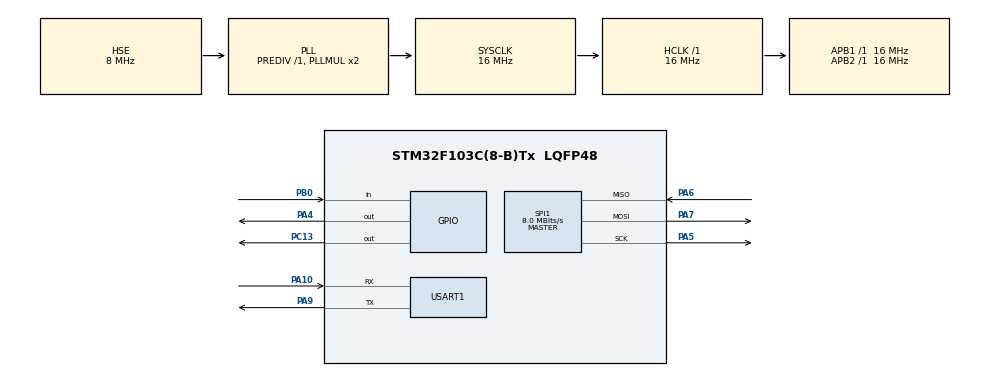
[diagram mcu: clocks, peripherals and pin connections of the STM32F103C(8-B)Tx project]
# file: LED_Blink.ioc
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FREERTOS.Tasks01=defaultTask,24,128,StartDefaultTask,Default,NULL,Dynamic,NULL,NULL;CANTxTask,24,256,StartCANTxTask,Default,NULL,Dynamic,NULL,NULL;UARTLogTask,8,256,StartUARTLogTask,Default,NULL,Dynamic,NULL,NULL
Mcu.Family=STM32F1
Mcu.Name=STM32F103C(8-B)Tx
Mcu.Package=LQFP48
NVIC.PriorityGroup=NVIC_PRIORITYGROUP_4
NVIC.USART1_IRQn=true\:5\:0\:false\:false\:true\:true\:true\:true\:true
PA10.Mode=Asynchronous
PA10.Signal=USART1_RX
PA13.Mode=Serial_Wire
PA13.Signal=SYS_JTMS-SWDIO
PA14.Mode=Serial_Wire
PA14.Signal=SYS_JTCK-SWCLK
PA4.Signal=GPIO_Output
PA5.Mode=Full_Duplex_Master
PA5.Signal=SPI1_SCK
PA6.Mode=Full_Duplex_Master
PA6.Signal=SPI1_MISO
PA7.Mode=Full_Duplex_Master
PA7.Signal=SPI1_MOSI
PA9.Mode=Asynchronous
PA9.Signal=USART1_TX
PB0.Signal=GPIO_Input
PC13-TAMPER-RTC.Signal=GPIO_Output
PD0-OSC_IN.Mode=HSE-External-Oscillator
PD0-OSC_IN.Signal=RCC_OSC_IN
PD1-OSC_OUT.Mode=HSE-External-Oscillator
PD1-OSC_OUT.Signal=RCC_OSC_OUT
ProjectManager.HeapSize=0x200
ProjectManager.StackSize=0x400
ProjectManager.TargetToolchain=STM32CubeIDE
RCC.AHBFreq_Value=16000000
RCC.APB1Freq_Value=16000000
RCC.APB1TimFreq_Value=16000000
RCC.APB2Freq_Value=16000000
RCC.APB2TimFreq_Value=16000000
RCC.HCLKFreq_Value=16000000
RCC.PLLSourceVirtual=RCC_PLLSOURCE_HSE
RCC.SYSCLKFreq_VALUE=16000000
RCC.SYSCLKSource=RCC_SYSCLKSOURCE_PLLCLK
RCC.USBFreq_Value=16000000
SPI1.CalculateBaudRate=8.0 MBits/s
SPI1.Direction=SPI_DIRECTION_2LINES
SPI1.Mode=SPI_MODE_MASTER
SPI1.VirtualType=VM_MASTER
USART1.VirtualMode=VM_ASYNC
VP_FREERTOS_VS_CMSIS_V2.Mode=CMSIS_V2
board=custom

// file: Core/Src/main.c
/* USER CODE BEGIN Header */
/**
  ******************************************************************************
  * @file           : main.c
  * @brief          : CAN Node1 - Sender with FreeRTOS
  ******************************************************************************
  */
/* USER CODE END Header */
#include "main.h"
#include "cmsis_os.h"

/* USER CODE BEGIN Includes */
#include "mcp2515.h"
#include <stdio.h>
#include <string.h>
/* USER CODE END Includes */

SPI_HandleTypeDef hspi1;

UART_HandleTypeDef huart1;

/* Definitions for defaultTask */
osThreadId_t defaultTaskHandle;
const osThreadAttr_t defaultTask_attributes = {
  .name = "defaultTask",
  .stack_size = 128 * 4,
  .priority = (osPriority_t) osPriorityNormal,
};
/* Definitions for CANTxTask */
osThreadId_t CANTxTaskHandle;
const osThreadAttr_t CANTxTask_attributes = {
  .name = "CANTxTask",
  .stack_size = 256 * 4,
  .priority = (osPriority_t) osPriorityNormal,
};
/* Definitions for UARTLogTask */
osThreadId_t UARTLogTaskHandle;
const osThreadAttr_t UARTLogTask_attributes = {
  .name = "UARTLogTask",
  .stack_size = 256 * 4,
  .priority = (osPriority_t) osPriorityLow,
};

void SystemClock_Config(void);
static void MX_GPIO_Init(void);
static void MX_USART1_UART_Init(void);
static void MX_SPI1_Init(void);
void StartDefaultTask(void *argument);
void StartCANTxTask(void *argument);
void StartUARTLogTask(void *argument);

int main(void)
{

  /* MCU Configuration--------------------------------------------------------*/

  /* Reset of all peripherals, Initializes the Flash interface and the Systick. */
  HAL_Init();

  /* Configure the system clock */
  SystemClock_Config();

  /* Initialize all configured peripherals */
  MX_GPIO_Init();
  MX_USART1_UART_Init();
  MX_SPI1_Init();
  /* USER CODE BEGIN 2 */
  MCP2515_Deselect();
  HAL_Delay(100);
  char msg[80];
  sprintf(msg, "Node1 FreeRTOS Booting...\r\n");
  HAL_UART_Transmit(&huart1, (uint8_t*)msg, strlen(msg), 100);
  /* USER CODE END 2 */

  /* Init scheduler */
  osKernelInitialize();

  /* USER CODE BEGIN RTOS_MUTEX */
  extern void MX_FREERTOS_Init(void);
  MX_FREERTOS_Init();
  /* USER CODE END RTOS_MUTEX */

  /* Create the thread(s) */
  /* creation of defaultTask */
  defaultTaskHandle = osThreadNew(StartDefaultTask, NULL, &defaultTask_attributes);

  /* creation of CANTxTask */
  CANTxTaskHandle = osThreadNew(StartCANTxTask, NULL, &CANTxTask_attributes);

  /* creation of UARTLogTask */
  UARTLogTaskHandle = osThreadNew(StartUARTLogTask, NULL, &UARTLogTask_attributes);

  /* Start scheduler */
  osKernelStart();

  /* We should never get here as control is now taken by the scheduler */

  /* Infinite loop */
  while (1)
  {

  }
}

void SystemClock_Config(void)
{
  RCC_OscInitTypeDef RCC_OscInitStruct = {0};
  RCC_ClkInitTypeDef RCC_ClkInitStruct = {0};

  /** Initializes the RCC Oscillators according to the specified parameters
  * in the RCC_OscInitTypeDef structure.
  */
  RCC_OscInitStruct.OscillatorType = RCC_OSCILLATORTYPE_HSE;
  RCC_OscInitStruct.HSEState = RCC_HSE_ON;
  RCC_OscInitStruct.HSEPredivValue = RCC_HSE_PREDIV_DIV1;
  RCC_OscInitStruct.HSIState = RCC_HSI_ON;
  RCC_OscInitStruct.PLL.PLLState = RCC_PLL_ON;
  RCC_OscInitStruct.PLL.PLLSource = RCC_PLLSOURCE_HSE;
  RCC_OscInitStruct.PLL.PLLMUL = RCC_PLL_MUL2;
  if (HAL_RCC_OscConfig(&RCC_OscInitStruct) != HAL_OK)
  {
    Error_Handler();
  }

  /** Initializes the CPU, AHB and APB buses clocks
  */
  RCC_ClkInitStruct.ClockType = RCC_CLOCKTYPE_HCLK|RCC_CLOCKTYPE_SYSCLK
                              |RCC_CLOCKTYPE_PCLK1|RCC_CLOCKTYPE_PCLK2;
  RCC_ClkInitStruct.SYSCLKSource = RCC_SYSCLKSOURCE_PLLCLK;
  RCC_ClkInitStruct.AHBCLKDivider = RCC_SYSCLK_DIV1;
  RCC_ClkInitStruct.APB1CLKDivider = RCC_HCLK_DIV1;
  RCC_ClkInitStruct.APB2CLKDivider = RCC_HCLK_DIV1;

  if (HAL_RCC_ClockConfig(&RCC_ClkInitStruct, FLASH_LATENCY_0) != HAL_OK)
  {
    Error_Handler();
  }
}

static void MX_SPI1_Init(void)
{

  /* SPI1 parameter configuration*/
  hspi1.Instance = SPI1;
  hspi1.Init.Mode = SPI_MODE_MASTER;
  hspi1.Init.Direction = SPI_DIRECTION_2LINES;
  hspi1.Init.DataSize = SPI_DATASIZE_8BIT;
  hspi1.Init.CLKPolarity = SPI_POLARITY_LOW;
  hspi1.Init.CLKPhase = SPI_PHASE_1EDGE;
  hspi1.Init.NSS = SPI_NSS_SOFT;
  hspi1.Init.BaudRatePrescaler = SPI_BAUDRATEPRESCALER_2;
  hspi1.Init.FirstBit = SPI_FIRSTBIT_MSB;
  hspi1.Init.TIMode = SPI_TIMODE_DISABLE;
  hspi1.Init.CRCCalculation = SPI_CRCCALCULATION_DISABLE;
  hspi1.Init.CRCPolynomial = 10;
  if (HAL_SPI_Init(&hspi1) != HAL_OK)
  {
    Error_Handler();
  }

}

static void MX_USART1_UART_Init(void)
{

  huart1.Instance = USART1;
  huart1.Init.BaudRate = 115200;
  huart1.Init.WordLength = UART_WORDLENGTH_8B;
  huart1.Init.StopBits = UART_STOPBITS_1;
  huart1.Init.Parity = UART_PARITY_NONE;
  huart1.Init.Mode = UART_MODE_TX_RX;
  huart1.Init.HwFlowCtl = UART_HWCONTROL_NONE;
  huart1.Init.OverSampling = UART_OVERSAMPLING_16;
  if (HAL_UART_Init(&huart1) != HAL_OK)
  {
    Error_Handler();
  }

}

static void MX_GPIO_Init(void)
{
  GPIO_InitTypeDef GPIO_InitStruct = {0};

  /* GPIO Ports Clock Enable */
  __HAL_RCC_GPIOC_CLK_ENABLE();
  __HAL_RCC_GPIOD_CLK_ENABLE();
  __HAL_RCC_GPIOA_CLK_ENABLE();
  __HAL_RCC_GPIOB_CLK_ENABLE();

  /*Configure GPIO pin Output Level */
  HAL_GPIO_WritePin(GPIOC, GPIO_PIN_13, GPIO_PIN_RESET);

  /*Configure GPIO pin Output Level */
  HAL_GPIO_WritePin(GPIOA, GPIO_PIN_4, GPIO_PIN_RESET);

  /*Configure GPIO pin : PC13 */
  GPIO_InitStruct.Pin = GPIO_PIN_13;
  GPIO_InitStruct.Mode = GPIO_MODE_OUTPUT_PP;
  GPIO_InitStruct.Pull = GPIO_NOPULL;
  GPIO_InitStruct.Speed = GPIO_SPEED_FREQ_LOW;
  HAL_GPIO_Init(GPIOC, &GPIO_InitStruct);

  /*Configure GPIO pin : PA4 */
  GPIO_InitStruct.Pin = GPIO_PIN_4;
  GPIO_InitStruct.Mode = GPIO_MODE_OUTPUT_PP;
  GPIO_InitStruct.Pull = GPIO_NOPULL;
  GPIO_InitStruct.Speed = GPIO_SPEED_FREQ_LOW;
  HAL_GPIO_Init(GPIOA, &GPIO_InitStruct);

  /*Configure GPIO pin : PB0 */
  GPIO_InitStruct.Pin = GPIO_PIN_0;
  GPIO_InitStruct.Mode = GPIO_MODE_INPUT;
  GPIO_InitStruct.Pull = GPIO_NOPULL;
  HAL_GPIO_Init(GPIOB, &GPIO_InitStruct);

}

/* USER CODE BEGIN Header_StartDefaultTask */

void Error_Handler(void)
{
  __disable_irq();
  while (1)
  {
  }
}

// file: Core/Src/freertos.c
#include "FreeRTOS.h"
#include "task.h"
#include "main.h"
#include "cmsis_os.h"
#include "mcp2515.h"
#include <stdio.h>
#include <string.h>
#include <stdlib.h>

extern UART_HandleTypeDef huart1;

osMutexId_t spiMutexHandle;
osMessageQueueId_t uartQueueHandle;

static uint8_t can_open = 0;
static uint8_t uart_rx_byte;
static char cmd_buf[32];
static int cmd_pos = 0;
static uint8_t cmd_ready = 0;
static char pending_cmd[32];

void StartDefaultTask(void *argument);
void StartCANTxTask(void *argument);
void StartUARTLogTask(void *argument);
void StartMonitorTask(void *argument);

void MX_FREERTOS_Init(void) {
    spiMutexHandle = osMutexNew(NULL);
}

void vApplicationStackOverflowHook(TaskHandle_t xTask, char *pcTaskName)
{
    HAL_UART_Transmit(&huart1, (uint8_t*)"STACK OVERFLOW: ", 16, 100);
    HAL_UART_Transmit(&huart1, (uint8_t*)pcTaskName, strlen(pcTaskName), 100);
    HAL_UART_Transmit(&huart1, (uint8_t*)"\r\n", 2, 100);
    while(1) {}
}

void HAL_UART_RxCpltCallback(UART_HandleTypeDef *huart)
{
    if (huart->Instance == USART1) {
        uint8_t byte = uart_rx_byte;
        if (byte == '\r' || byte == '\n') {
            if (cmd_pos > 0) {
                cmd_buf[cmd_pos] = 0;
                memcpy(pending_cmd, cmd_buf, cmd_pos + 1);
                cmd_ready = 1;
                cmd_pos = 0;
                memset(cmd_buf, 0, sizeof(cmd_buf));
            }
        } else if (cmd_pos < 31) {
            cmd_buf[cmd_pos++] = byte;
        }

        HAL_UART_Receive_IT(&huart1, &uart_rx_byte, 1);
    }
}

void slcan_parse(char *cmd)
{
    char debug[40];
    sprintf(debug, "CMD:[%s]\r\n", cmd);
    HAL_UART_Transmit(&huart1, (uint8_t*)debug, strlen(debug), 100);

    uint8_t response = '\r';

    if (cmd[0] == 'S') {
        HAL_UART_Transmit(&huart1, &response, 1, 100);
    }
    else if (cmd[0] == 'O') {
        can_open = 1;
        HAL_UART_Transmit(&huart1, &response, 1, 100);
    }
    else if (cmd[0] == 'C') {
        can_open = 0;
        HAL_UART_Transmit(&huart1, &response, 1, 100);
    }
    else if (cmd[0] == 't' && can_open) {
        uint16_t id = 0;
        uint8_t dlc = 0;
        uint8_t data[8] = {0};

        char id_str[4] = {cmd[1], cmd[2], cmd[3], 0};
        id = (uint16_t)strtol(id_str, NULL, 16);

        dlc = cmd[4] - '0';
        if (dlc > 8) dlc = 8;

        for (int i = 0; i < dlc; i++) {
            char byte_str[3] = {cmd[5 + i*2], cmd[6 + i*2], 0};
            data[i] = (uint8_t)strtol(byte_str, NULL, 16);
        }

        char tx_debug[40];
        sprintf(tx_debug, "TX ID=0x%03X DLC=%d\r\n", id, dlc);
        HAL_UART_Transmit(&huart1, (uint8_t*)tx_debug, strlen(tx_debug), 100);

        osMutexAcquire(spiMutexHandle, osWaitForever);
        MCP2515_SendFrame(id, data, dlc);
        osMutexRelease(spiMutexHandle);

        HAL_UART_Transmit(&huart1, &response, 1, 100);
    }
    else if (cmd[0] == 'F') {
        osMutexAcquire(spiMutexHandle, osWaitForever);
        uint8_t eflg = MCP2515_ReadRegister(0x2D);
        osMutexRelease(spiMutexHandle);
        char resp[8];
        sprintf(resp, "F%02X\r", eflg);
        HAL_UART_Transmit(&huart1, (uint8_t*)resp, strlen(resp), 100);
    }
    else if (cmd[0] == 'V') {
        HAL_UART_Transmit(&huart1, (uint8_t*)"V0101\r", 6, 100);
    }
    else {
        uint8_t err = 0x07;
        HAL_UART_Transmit(&huart1, &err, 1, 100);
    }
}

void slcan_receive(void)
{
    uint8_t canintf = MCP2515_ReadRegister(0x2C);
    if (!(canintf & 0x03)) return;

    uint8_t cmd = (canintf & 0x01) ? 0x90 : 0x94;
    uint8_t buf[13] = {0};
    MCP2515_Select();
    HAL_SPI_Transmit(&hspi1, &cmd, 1, 100);
    HAL_SPI_Receive(&hspi1, buf, 13, 100);
    MCP2515_Deselect();

    uint16_t id = ((uint16_t)buf[0] << 3) | (buf[1] >> 5);
    uint8_t dlc = buf[4] & 0x0F;

    char slcan_msg[32];
    int pos = 0;
    pos += sprintf(slcan_msg + pos, "t%03X%d", id, dlc);
    for (int i = 0; i < dlc; i++) {
        pos += sprintf(slcan_msg + pos, "%02X", buf[5 + i]);
    }
    slcan_msg[pos++] = '\r';
    slcan_msg[pos] = 0;

    HAL_UART_Transmit(&huart1, (uint8_t*)slcan_msg, pos, 100);

    uint8_t clr[3] = {0x05, 0x2C, (uint8_t)(canintf & 0x01 ? ~0x01 : ~0x02)};
    MCP2515_Select();
    HAL_SPI_Transmit(&hspi1, clr, 3, 100);
    MCP2515_Deselect();
}

void StartDefaultTask(void *argument)
{
    for(;;)
    {
        HAL_GPIO_TogglePin(GPIOC, GPIO_PIN_13);
        osDelay(500);
    }
}

void StartCANTxTask(void *argument)
{
    osDelay(200);

    osMutexAcquire(spiMutexHandle, osWaitForever);
    MCP2515_Init();
    osMutexRelease(spiMutexHandle);

    HAL_UART_Transmit(&huart1, (uint8_t*)"slcan gateway ready\r\n", 21, 100);

    HAL_UART_Receive_IT(&huart1, &uart_rx_byte, 1);

    for(;;)
    {

        if (cmd_ready) {
            cmd_ready = 0;
            slcan_parse(pending_cmd);
        }

        if (can_open) {
            osMutexAcquire(spiMutexHandle, osWaitForever);
            slcan_receive();
            osMutexRelease(spiMutexHandle);
        }

        osDelay(1);
    }
}

void StartUARTLogTask(void *argument)
{
    for(;;)
    {
        osDelay(1000);
    }
}

void StartMonitorTask(void *argument)
{
    for(;;)
    {
        osDelay(5000);
    }
}
